# A8107M register map
Vendor: Amiccom Electronics Co., Ltd.; Series: A8107M; File version: 1.0
CPU: CM0 r0p0, little endian, no MPU, no FPU, 2 interrupt priority bits
Registers are 32-bit, read-write, reset 0x0 unless marked. A register's access mark holds for its fields unless they carry their own. Offsets are from the block's base; [hi:lo] are bit positions; {n}, {i} and the like mark numbered series; 'fields as' and 'values as' point back to an identical list.

## GPIO0 (part 2 of 2) — General Purpose I/O
Base 0x40010000
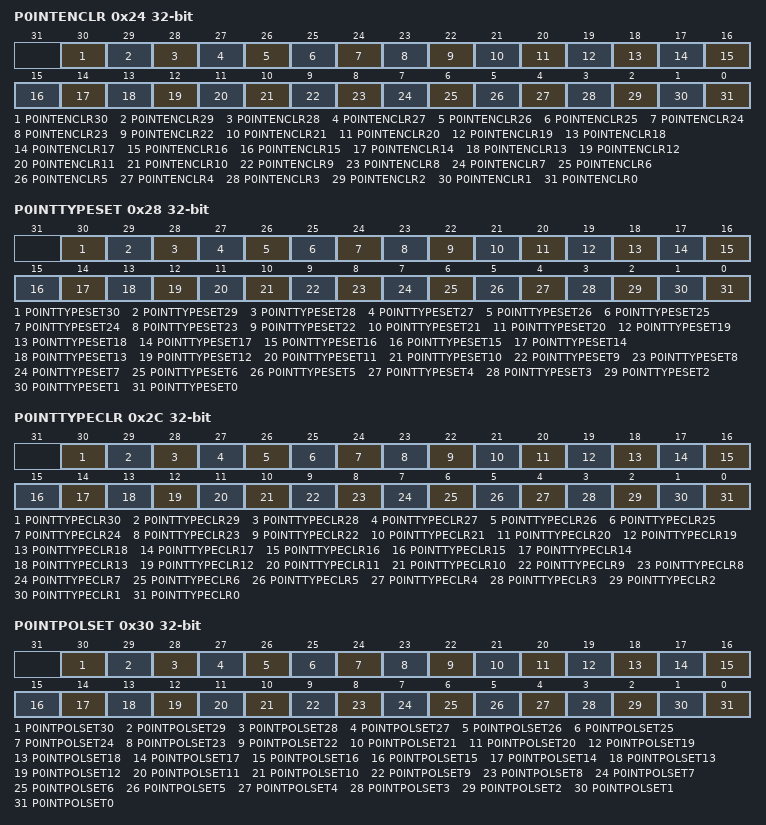
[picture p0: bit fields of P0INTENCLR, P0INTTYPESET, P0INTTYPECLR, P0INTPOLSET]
0x24 P0INTENCLR — Port 0 Interrupt Enable Clear Register
  [30] P0INTENCLR30 — Interrupt Enable Clear of GPIO0.30
    0=No effect; 1=Interrupt Enable Clear of GPIO0.30
  [29] P0INTENCLR29 — Interrupt Enable Clear of GPIO0.29
    0=No effect; 1=Interrupt Enable Clear of GPIO0.29
  [28] P0INTENCLR28 — Interrupt Enable Clear of GPIO0.28
    0=No effect; 1=Interrupt Enable Clear of GPIO0.28
  [27] P0INTENCLR27 — Interrupt Enable Clear of GPIO0.27
    0=No effect; 1=No effect
  [26] P0INTENCLR26 — Interrupt Enable Clear of GPIO0.26
    0=No effect; 1=Interrupt Enable Clear of GPIO0.26
  [25] P0INTENCLR25 — Interrupt Enable Clear of GPIO0.25
    0=No effect; 1=Interrupt Enable Clear of GPIO0.25
  [24] P0INTENCLR24 — Interrupt Enable Clear of GPIO0.24
    0=No effect; 1=Interrupt Enable Clear of GPIO0.24
  [23] P0INTENCLR23 — Interrupt Enable Clear of GPIO0.23
    0=No effect; 1=Interrupt Enable Clear of GPIO0.23
  [22] P0INTENCLR22 — Interrupt Enable Clear of GPIO0.22
    0=No effect; 1=Interrupt Enable Clear of GPIO0.22
  [21] P0INTENCLR21 — Interrupt Enable Clear of GPIO0.21
    0=No effect; 1=Interrupt Enable Clear of GPIO0.21
  [20] P0INTENCLR20 — Interrupt Enable Clear of GPIO0.20
    0=No effect; 1=Interrupt Enable Clear of GPIO0.20
  [19] P0INTENCLR19 — Interrupt Enable Clear of GPIO0.19
    0=No effect; 1=Interrupt Enable Clear of GPIO0.19
  [18] P0INTENCLR18 — Interrupt Enable Clear of GPIO0.18
    0=No effect; 1=Interrupt Enable Clear of GPIO0.18
  [17] P0INTENCLR17 — Interrupt Enable Clear of GPIO0.17
    0=No effect; 1=Interrupt Enable Clear of GPIO0.17
  [16] P0INTENCLR16 — Interrupt Enable Clear of GPIO0.16
    0=No effect; 1=Interrupt Enable Clear of GPIO0.16
  [15] P0INTENCLR15 — Interrupt Enable Clear of GPIO0.15
    0=No effect; 1=Interrupt Enable Clear of GPIO0.15
  [14] P0INTENCLR14 — Interrupt Enable Clear of GPIO0.14
    0=No effect; 1=Interrupt Enable Clear of GPIO0.14
  [13] P0INTENCLR13 — Interrupt Enable Clear of GPIO0.13
    0=No effect; 1=Interrupt Enable Clear of GPIO0.13
  [12] P0INTENCLR12 — Interrupt Enable Clear of GPIO0.12
    0=No effect; 1=Interrupt Enable Clear of GPIO0.12
  [11] P0INTENCLR11 — Interrupt Enable Clear of GPIO0.11
    0=No effect; 1=Interrupt Enable Clear of GPIO0.11
  [10] P0INTENCLR10 — Interrupt Enable Clear of GPIO0.10
    0=No effect; 1=Interrupt Enable Clear of GPIO0.10
  [9] P0INTENCLR9 — Interrupt Enable Clear of GPIO0.9
    0=No effect; 1=Interrupt Enable Clear of GPIO0.9
  [8] P0INTENCLR8 — Interrupt Enable Clear of GPIO0.8
    0=No effect; 1=Interrupt Enable Clear of GPIO0.8
  [7] P0INTENCLR7 — Interrupt Enable Clear of GPIO0.7
    0=No effect; 1=Interrupt Enable Clear of GPIO0.7
  [6] P0INTENCLR6 — Interrupt Enable Clear of GPIO0.6
    0=No effect; 1=Interrupt Enable Clear of GPIO0.6
  [5] P0INTENCLR5 — Interrupt Enable Clear of GPIO0.5
    0=No effect; 1=Interrupt Enable Clear of GPIO0.5
  [4] P0INTENCLR4 — Interrupt Enable Clear of GPIO0.4
    0=No effect; 1=Interrupt Enable Clear of GPIO0.4
  [3] P0INTENCLR3 — Interrupt Enable Clear of GPIO0.3
    0=No effect; 1=Interrupt Enable Clear of GPIO0.3
  [2] P0INTENCLR2 — Interrupt Enable Clear of GPIO0.2
    0=No effect; 1=Interrupt Enable Clear of GPIO0.2
  [1] P0INTENCLR1 — Interrupt Enable Clear of GPIO0.1
    0=No effect; 1=Interrupt Enable Clear of GPIO0.1
  [0] P0INTENCLR0 — Interrupt Enable Clear of GPIO0.0
    0=No effect; 1=Interrupt Enable Clear of GPIO0.0
0x28 P0INTTYPESET — Port 0 Interrupt Type Set Register
  [30] P0INTTYPESET30 — Interrupt type set (interrupt by edge) of GPIO0.30
    0=No effect; 1=Interrupt type set (interrupt by edge) of GPIO0.30
  [29] P0INTTYPESET29 — Interrupt type set (interrupt by edge) of GPIO0.29
    0=No effect; 1=Interrupt type set (interrupt by edge) of GPIO0.29
  [28] P0INTTYPESET28 — Interrupt type set (interrupt by edge) of GPIO0.28
    0=No effect; 1=Interrupt type set (interrupt by edge) of GPIO0.28
  [27] P0INTTYPESET27 — Interrupt type set (interrupt by edge) of GPIO0.27
    0=No effect; 1=No effect
  [26] P0INTTYPESET26 — Interrupt type set (interrupt by edge) of GPIO0.26
    0=No effect; 1=Interrupt type set (interrupt by edge) of GPIO0.26
  [25] P0INTTYPESET25 — Interrupt type set (interrupt by edge) of GPIO0.25
    0=No effect; 1=Interrupt type set (interrupt by edge) of GPIO0.25
  [24] P0INTTYPESET24 — Interrupt type set (interrupt by edge) of GPIO0.24
    0=No effect; 1=Interrupt type set (interrupt by edge) of GPIO0.24
  [23] P0INTTYPESET23 — Interrupt type set (interrupt by edge) of GPIO0.23
    0=No effect; 1=Interrupt type set (interrupt by edge) of GPIO0.23
  [22] P0INTTYPESET22 — Interrupt type set (interrupt by edge) of GPIO0.22
    0=No effect; 1=Interrupt type set (interrupt by edge) of GPIO0.22
  [21] P0INTTYPESET21 — Interrupt type set (interrupt by edge) of GPIO0.21
    0=No effect; 1=Interrupt type set (interrupt by edge) of GPIO0.21
  [20] P0INTTYPESET20 — Interrupt type set (interrupt by edge) of GPIO0.20
    0=No effect; 1=Interrupt type set (interrupt by edge) of GPIO0.20
  [19] P0INTTYPESET19 — Interrupt type set (interrupt by edge) of GPIO0.19
    0=No effect; 1=Interrupt type set (interrupt by edge) of GPIO0.19
  [18] P0INTTYPESET18 — Interrupt type set (interrupt by edge) of GPIO0.18
    0=No effect; 1=Interrupt type set (interrupt by edge) of GPIO0.18
  [17] P0INTTYPESET17 — Interrupt type set (interrupt by edge) of GPIO0.17
    0=No effect; 1=Interrupt type set (interrupt by edge) of GPIO0.17
  [16] P0INTTYPESET16 — Interrupt type set (interrupt by edge) of GPIO0.16
    0=No effect; 1=Interrupt type set (interrupt by edge) of GPIO0.16
  [15] P0INTTYPESET15 — Interrupt type set (interrupt by edge) of GPIO0.15
    0=No effect; 1=Interrupt type set (interrupt by edge) of GPIO0.15
  [14] P0INTTYPESET14 — Interrupt type set (interrupt by edge) of GPIO0.14
    0=No effect; 1=Interrupt type set (interrupt by edge) of GPIO0.14
  [13] P0INTTYPESET13 — Interrupt type set (interrupt by edge) of GPIO0.13
    0=No effect; 1=Interrupt type set (interrupt by edge) of GPIO0.13
  [12] P0INTTYPESET12 — Interrupt type set (interrupt by edge) of GPIO0.12
    0=No effect; 1=Interrupt type set (interrupt by edge) of GPIO0.12
  [11] P0INTTYPESET11 — Interrupt type set (interrupt by edge) of GPIO0.11
    0=No effect; 1=Interrupt type set (interrupt by edge) of GPIO0.11
  [10] P0INTTYPESET10 — Interrupt type set (interrupt by edge) of GPIO0.10
    0=No effect; 1=Interrupt type set (interrupt by edge) of GPIO0.10
  [9] P0INTTYPESET9 — Interrupt type set (interrupt by edge) of GPIO0.9
    0=No effect; 1=Interrupt type set (interrupt by edge) of GPIO0.9
  [8] P0INTTYPESET8 — Interrupt type set (interrupt by edge) of GPIO0.8
    0=No effect; 1=Interrupt type set (interrupt by edge) of GPIO0.8
  [7] P0INTTYPESET7 — Interrupt type set (interrupt by edge) of GPIO0.7
    0=No effect; 1=Interrupt type set (interrupt by edge) of GPIO0.7
  [6] P0INTTYPESET6 — Interrupt type set (interrupt by edge) of GPIO0.6
    0=No effect; 1=Interrupt type set (interrupt by edge) of GPIO0.6
  [5] P0INTTYPESET5 — Interrupt type set (interrupt by edge) of GPIO0.5
    0=No effect; 1=Interrupt type set (interrupt by edge) of GPIO0.5
  [4] P0INTTYPESET4 — Interrupt type set (interrupt by edge) of GPIO0.4
    0=No effect; 1=Interrupt type set (interrupt by edge) of GPIO0.4
  [3] P0INTTYPESET3 — Interrupt type set (interrupt by edge) of GPIO0.3
    0=No effect; 1=Interrupt type set (interrupt by edge) of GPIO0.3
  [2] P0INTTYPESET2 — Interrupt type set (interrupt by edge) of GPIO0.2
    0=No effect; 1=Interrupt type set (interrupt by edge) of GPIO0.2
  [1] P0INTTYPESET1 — Interrupt type set (interrupt by edge) of GPIO0.1
    0=No effect; 1=Interrupt type set (interrupt by edge) of GPIO0.1
  [0] P0INTTYPESET0 — Interrupt type set (interrupt by edge) of GPIO0.0
    0=No effect; 1=Interrupt type set (interrupt by edge) of GPIO0.0
0x2C P0INTTYPECLR — Port 0 Interrupt Type Clear Register
  [30] P0INTTYPECLR30 — Interrupt type clean (interrupt by level) of GPIO0.30
    0=No effect; 1=Interrupt type clean (interrupt by level) of GPIO0.30
  [29] P0INTTYPECLR29 — Interrupt type clean (interrupt by level) of GPIO0.29
    0=No effect; 1=Interrupt type clean (interrupt by level) of GPIO0.29
  [28] P0INTTYPECLR28 — Interrupt type clean (interrupt by level) of GPIO0.28
    0=No effect; 1=Interrupt type clean (interrupt by level) of GPIO0.28
  [27] P0INTTYPECLR27 — Interrupt type clean (interrupt by level) of GPIO0.27
    0=No effect; 1=No effect
  [26] P0INTTYPECLR26 — Interrupt type clean (interrupt by level) of GPIO0.26
    0=No effect; 1=Interrupt type clean (interrupt by level) of GPIO0.26
  [25] P0INTTYPECLR25 — Interrupt type clean (interrupt by level) of GPIO0.25
    0=No effect; 1=Interrupt type clean (interrupt by level) of GPIO0.25
  [24] P0INTTYPECLR24 — Interrupt type clean (interrupt by level) of GPIO0.24
    0=No effect; 1=Interrupt type clean (interrupt by level) of GPIO0.24
  [23] P0INTTYPECLR23 — Interrupt type clean (interrupt by level) of GPIO0.23
    0=No effect; 1=Interrupt type clean (interrupt by level) of GPIO0.23
  [22] P0INTTYPECLR22 — Interrupt type clean (interrupt by level) of GPIO0.22
    0=No effect; 1=Interrupt type clean (interrupt by level) of GPIO0.22
  [21] P0INTTYPECLR21 — Interrupt type clean (interrupt by level) of GPIO0.21
    0=No effect; 1=Interrupt type clean (interrupt by level) of GPIO0.21
  [20] P0INTTYPECLR20 — Interrupt type clean (interrupt by level) of GPIO0.20
    0=No effect; 1=Interrupt type clean (interrupt by level) of GPIO0.20
  [19] P0INTTYPECLR19 — Interrupt type clean (interrupt by level) of GPIO0.19
    0=No effect; 1=Interrupt type clean (interrupt by level) of GPIO0.19
  [18] P0INTTYPECLR18 — Interrupt type clean (interrupt by level) of GPIO0.18
    0=No effect; 1=Interrupt type clean (interrupt by level) of GPIO0.18
  [17] P0INTTYPECLR17 — Interrupt type clean (interrupt by level) of GPIO0.17
    0=No effect; 1=Interrupt type clean (interrupt by level) of GPIO0.17
  [16] P0INTTYPECLR16 — Interrupt type clean (interrupt by level) of GPIO0.16
    0=No effect; 1=Interrupt type clean (interrupt by level) of GPIO0.16
  [15] P0INTTYPECLR15 — Interrupt type clean (interrupt by level) of GPIO0.15
    0=No effect; 1=Interrupt type clean (interrupt by level) of GPIO0.15
  [14] P0INTTYPECLR14 — Interrupt type clean (interrupt by level) of GPIO0.14
    0=No effect; 1=Interrupt type clean (interrupt by level) of GPIO0.14
  [13] P0INTTYPECLR13 — Interrupt type clean (interrupt by level) of GPIO0.13
    0=No effect; 1=Interrupt type clean (interrupt by level) of GPIO0.13
  [12] P0INTTYPECLR12 — Interrupt type clean (interrupt by level) of GPIO0.12
    0=No effect; 1=Interrupt type clean (interrupt by level) of GPIO0.12
  [11] P0INTTYPECLR11 — Interrupt type clean (interrupt by level) of GPIO0.11
    0=No effect; 1=Interrupt type clean (interrupt by level) of GPIO0.11
  [10] P0INTTYPECLR10 — Interrupt type clean (interrupt by level) of GPIO0.10
    0=No effect; 1=Interrupt type clean (interrupt by level) of GPIO0.10
  [9] P0INTTYPECLR9 — Interrupt type clean (interrupt by level) of GPIO0.9
    0=No effect; 1=Interrupt type clean (interrupt by level) of GPIO0.9
  [8] P0INTTYPECLR8 — Interrupt type clean (interrupt by level) of GPIO0.8
    0=No effect; 1=Interrupt type clean (interrupt by level) of GPIO0.8
  [7] P0INTTYPECLR7 — Interrupt type clean (interrupt by level) of GPIO0.7
    0=No effect; 1=Interrupt type clean (interrupt by level) of GPIO0.7
  [6] P0INTTYPECLR6 — Interrupt type clean (interrupt by level) of GPIO0.6
    0=No effect; 1=Interrupt type clean (interrupt by level) of GPIO0.6
  [5] P0INTTYPECLR5 — Interrupt type clean (interrupt by level) of GPIO0.5
    0=No effect; 1=Interrupt type clean (interrupt by level) of GPIO0.5
  [4] P0INTTYPECLR4 — Interrupt type clean (interrupt by level) of GPIO0.4
    0=No effect; 1=Interrupt type clean (interrupt by level) of GPIO0.4
  [3] P0INTTYPECLR3 — Interrupt type clean (interrupt by level) of GPIO0.3
    0=No effect; 1=Interrupt type clean (interrupt by level) of GPIO0.3
  [2] P0INTTYPECLR2 — Interrupt type clean (interrupt by level) of GPIO0.2
    0=No effect; 1=Interrupt type clean (interrupt by level) of GPIO0.2
  [1] P0INTTYPECLR1 — Interrupt type clean (interrupt by level) of GPIO0.1
    0=No effect; 1=Interrupt type clean (interrupt by level) of GPIO0.1
  [0] P0INTTYPECLR0 — Interrupt type clean (interrupt by level) of GPIO0.0
    0=No effect; 1=Interrupt type clean (interrupt by level) of GPIO0.0
0x30 P0INTPOLSET — Port 0 Interrupt Polarity Set Register
  [30] P0INTPOLSET30 — Interrupt Polarity-level clean (low level or falling edge) of GPIO0.30
    0=No effect; 1=Interrupt Polarity-level clean (low level or falling edge) of GPIO0.30
  [29] P0INTPOLSET29 — Interrupt Polarity-level clean (low level or falling edge) of GPIO0.29
    0=No effect; 1=Interrupt Polarity-level clean (low level or falling edge) of GPIO0.29
  [28] P0INTPOLSET28 — Interrupt Polarity-level clean (low level or falling edge) of GPIO0.28
    0=No effect; 1=Interrupt Polarity-level clean (low level or falling edge) of GPIO0.28
  [27] P0INTPOLSET27 — Interrupt Polarity-level clean (low level or falling edge) of GPIO0.27
    0=No effect; 1=No effect
  [26] P0INTPOLSET26 — Interrupt Polarity-level clean (low level or falling edge) of GPIO0.26
    0=No effect; 1=Interrupt Polarity-level clean (low level or falling edge) of GPIO0.26
  [25] P0INTPOLSET25 — Interrupt Polarity-level clean (low level or falling edge) of GPIO0.25
    0=No effect; 1=Interrupt Polarity-level clean (low level or falling edge) of GPIO0.25
  [24] P0INTPOLSET24 — Interrupt Polarity-level clean (low level or falling edge) of GPIO0.24
    0=No effect; 1=Interrupt Polarity-level clean (low level or falling edge) of GPIO0.24
  [23] P0INTPOLSET23 — Interrupt Polarity-level clean (low level or falling edge) of GPIO0.23
    0=No effect; 1=Interrupt Polarity-level clean (low level or falling edge) of GPIO0.23
  [22] P0INTPOLSET22 — Interrupt Polarity-level clean (low level or falling edge) of GPIO0.22
    0=No effect; 1=Interrupt Polarity-level clean (low level or falling edge) of GPIO0.22
  [21] P0INTPOLSET21 — Interrupt Polarity-level clean (low level or falling edge) of GPIO0.21
    0=No effect; 1=Interrupt Polarity-level clean (low level or falling edge) of GPIO0.21
  [20] P0INTPOLSET20 — Interrupt Polarity-level clean (low level or falling edge) of GPIO0.20
    0=No effect; 1=Interrupt Polarity-level clean (low level or falling edge) of GPIO0.20
  [19] P0INTPOLSET19 — Interrupt Polarity-level clean (low level or falling edge) of GPIO0.19
    0=No effect; 1=Interrupt Polarity-level clean (low level or falling edge) of GPIO0.19
  [18] P0INTPOLSET18 — Interrupt Polarity-level clean (low level or falling edge) of GPIO0.18
    0=No effect; 1=Interrupt Polarity-level clean (low level or falling edge) of GPIO0.18
  [17] P0INTPOLSET17 — Interrupt Polarity-level clean (low level or falling edge) of GPIO0.17
    0=No effect; 1=Interrupt Polarity-level clean (low level or falling edge) of GPIO0.17
  [16] P0INTPOLSET16 — Interrupt Polarity-level clean (low level or falling edge) of GPIO0.16
    0=No effect; 1=Interrupt Polarity-level clean (low level or falling edge) of GPIO0.16
  [15] P0INTPOLSET15 — Interrupt Polarity-level clean (low level or falling edge) of GPIO0.15
    0=No effect; 1=Interrupt Polarity-level clean (low level or falling edge) of GPIO0.15
  [14] P0INTPOLSET14 — Interrupt Polarity-level clean (low level or falling edge) of GPIO0.14
    0=No effect; 1=Interrupt Polarity-level clean (low level or falling edge) of GPIO0.14
  [13] P0INTPOLSET13 — Interrupt Polarity-level clean (low level or falling edge) of GPIO0.13
    0=No effect; 1=Interrupt Polarity-level clean (low level or falling edge) of GPIO0.13
  [12] P0INTPOLSET12 — Interrupt Polarity-level clean (low level or falling edge) of GPIO0.12
    0=No effect; 1=Interrupt Polarity-level clean (low level or falling edge) of GPIO0.12
  [11] P0INTPOLSET11 — Interrupt Polarity-level clean (low level or falling edge) of GPIO0.11
    0=No effect; 1=Interrupt Polarity-level clean (low level or falling edge) of GPIO0.11
  [10] P0INTPOLSET10 — Interrupt Polarity-level clean (low level or falling edge) of GPIO0.10
    0=No effect; 1=Interrupt Polarity-level clean (low level or falling edge) of GPIO0.10
  [9] P0INTPOLSET9 — Interrupt Polarity-level clean (low level or falling edge) of GPIO0.9
    0=No effect; 1=Interrupt Polarity-level clean (low level or falling edge) of GPIO0.9
  [8] P0INTPOLSET8 — Interrupt Polarity-level clean (low level or falling edge) of GPIO0.8
    0=No effect; 1=Interrupt Polarity-level clean (low level or falling edge) of GPIO0.8
  [7] P0INTPOLSET7 — Interrupt Polarity-level clean (low level or falling edge) of GPIO0.7
    0=No effect; 1=Interrupt Polarity-level clean (low level or falling edge) of GPIO0.7
  [6] P0INTPOLSET6 — Interrupt Polarity-level clean (low level or falling edge) of GPIO0.6
    0=No effect; 1=Interrupt Polarity-level clean (low level or falling edge) of GPIO0.6
  [5] P0INTPOLSET5 — Interrupt Polarity-level clean (low level or falling edge) of GPIO0.5
    0=No effect; 1=Interrupt Polarity-level clean (low level or falling edge) of GPIO0.5
  [4] P0INTPOLSET4 — Interrupt Polarity-level clean (low level or falling edge) of GPIO0.4
    0=No effect; 1=Interrupt Polarity-level clean (low level or falling edge) of GPIO0.4
  [3] P0INTPOLSET3 — Interrupt Polarity-level clean (low level or falling edge) of GPIO0.3
    0=No effect; 1=Interrupt Polarity-level clean (low level or falling edge) of GPIO0.3
  [2] P0INTPOLSET2 — Interrupt Polarity-level clean (low level or falling edge) of GPIO0.2
    0=No effect; 1=Interrupt Polarity-level clean (low level or falling edge) of GPIO0.2
  [1] P0INTPOLSET1 — Interrupt Polarity-level clean (low level or falling edge) of GPIO0.1
    0=No effect; 1=Interrupt Polarity-level clean (low level or falling edge) of GPIO0.1
  [0] P0INTPOLSET0 — Interrupt Polarity-level clean (low level or falling edge) of GPIO0.0
    0=No effect; 1=Interrupt Polarity-level clean (low level or falling edge) of GPIO0.0
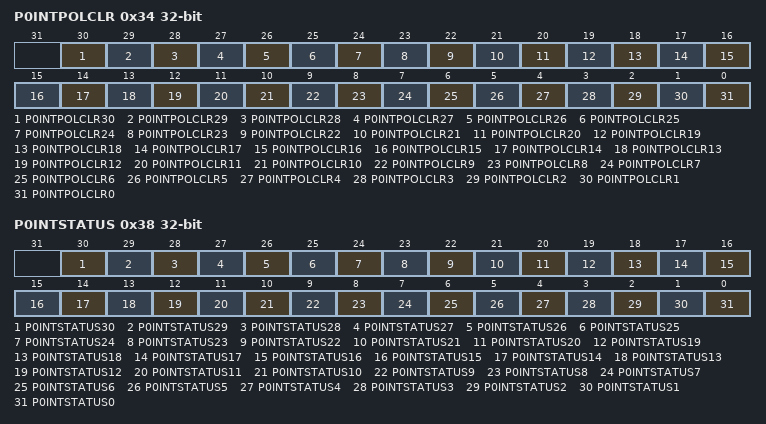
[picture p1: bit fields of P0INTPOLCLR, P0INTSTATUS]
0x34 P0INTPOLCLR — Port 0 Interrupt Polarity Clear Register
  [30] P0INTPOLCLR30 — Interrupt Polarity-level clean (low level or falling edge) of GPIO0.30
    values as P0INTPOLSET.P0INTPOLSET30
  [29] P0INTPOLCLR29 — Interrupt Polarity-level clean (low level or falling edge) of GPIO0.29
    values as P0INTPOLSET.P0INTPOLSET29
  [28] P0INTPOLCLR28 — Interrupt Polarity-level clean (low level or falling edge) of GPIO0.28
    values as P0INTPOLSET.P0INTPOLSET28
  [27] P0INTPOLCLR27 — Interrupt Polarity-level clean (low level or falling edge) of GPIO0.27
    0=No effect; 1=No effect
  [26] P0INTPOLCLR26 — Interrupt Polarity-level clean (low level or falling edge) of GPIO0.26
    values as P0INTPOLSET.P0INTPOLSET26
  [25] P0INTPOLCLR25 — Interrupt Polarity-level clean (low level or falling edge) of GPIO0.25
    values as P0INTPOLSET.P0INTPOLSET25
  [24] P0INTPOLCLR24 — Interrupt Polarity-level clean (low level or falling edge) of GPIO0.24
    values as P0INTPOLSET.P0INTPOLSET24
  [23] P0INTPOLCLR23 — Interrupt Polarity-level clean (low level or falling edge) of GPIO0.23
    values as P0INTPOLSET.P0INTPOLSET23
  [22] P0INTPOLCLR22 — Interrupt Polarity-level clean (low level or falling edge) of GPIO0.22
    values as P0INTPOLSET.P0INTPOLSET22
  [21] P0INTPOLCLR21 — Interrupt Polarity-level clean (low level or falling edge) of GPIO0.21
    values as P0INTPOLSET.P0INTPOLSET21
  [20] P0INTPOLCLR20 — Interrupt Polarity-level clean (low level or falling edge) of GPIO0.20
    values as P0INTPOLSET.P0INTPOLSET20
  [19] P0INTPOLCLR19 — Interrupt Polarity-level clean (low level or falling edge) of GPIO0.19
    values as P0INTPOLSET.P0INTPOLSET19
  [18] P0INTPOLCLR18 — Interrupt Polarity-level clean (low level or falling edge) of GPIO0.18
    values as P0INTPOLSET.P0INTPOLSET18
  [17] P0INTPOLCLR17 — Interrupt Polarity-level clean (low level or falling edge) of GPIO0.17
    values as P0INTPOLSET.P0INTPOLSET17
  [16] P0INTPOLCLR16 — Interrupt Polarity-level clean (low level or falling edge) of GPIO0.16
    values as P0INTPOLSET.P0INTPOLSET16
  [15] P0INTPOLCLR15 — Interrupt Polarity-level clean (low level or falling edge) of GPIO0.15
    values as P0INTPOLSET.P0INTPOLSET15
  [14] P0INTPOLCLR14 — Interrupt Polarity-level clean (low level or falling edge) of GPIO0.14
    values as P0INTPOLSET.P0INTPOLSET14
  [13] P0INTPOLCLR13 — Interrupt Polarity-level clean (low level or falling edge) of GPIO0.13
    values as P0INTPOLSET.P0INTPOLSET13
  [12] P0INTPOLCLR12 — Interrupt Polarity-level clean (low level or falling edge) of GPIO0.12
    values as P0INTPOLSET.P0INTPOLSET12
  [11] P0INTPOLCLR11 — Interrupt Polarity-level clean (low level or falling edge) of GPIO0.11
    values as P0INTPOLSET.P0INTPOLSET11
  [10] P0INTPOLCLR10 — Interrupt Polarity-level clean (low level or falling edge) of GPIO0.10
    values as P0INTPOLSET.P0INTPOLSET10
  [9] P0INTPOLCLR9 — Interrupt Polarity-level clean (low level or falling edge) of GPIO0.9
    values as P0INTPOLSET.P0INTPOLSET9
  [8] P0INTPOLCLR8 — Interrupt Polarity-level clean (low level or falling edge) of GPIO0.8
    values as P0INTPOLSET.P0INTPOLSET8
  [7] P0INTPOLCLR7 — Interrupt Polarity-level clean (low level or falling edge) of GPIO0.7
    values as P0INTPOLSET.P0INTPOLSET7
  [6] P0INTPOLCLR6 — Interrupt Polarity-level clean (low level or falling edge) of GPIO0.6
    values as P0INTPOLSET.P0INTPOLSET6
  [5] P0INTPOLCLR5 — Interrupt Polarity-level clean (low level or falling edge) of GPIO0.5
    values as P0INTPOLSET.P0INTPOLSET5
  [4] P0INTPOLCLR4 — Interrupt Polarity-level clean (low level or falling edge) of GPIO0.4
    values as P0INTPOLSET.P0INTPOLSET4
  [3] P0INTPOLCLR3 — Interrupt Polarity-level clean (low level or falling edge) of GPIO0.3
    values as P0INTPOLSET.P0INTPOLSET3
  [2] P0INTPOLCLR2 — Interrupt Polarity-level clean (low level or falling edge) of GPIO0.2
    values as P0INTPOLSET.P0INTPOLSET2
  [1] P0INTPOLCLR1 — Interrupt Polarity-level clean (low level or falling edge) of GPIO0.1
    values as P0INTPOLSET.P0INTPOLSET1
  [0] P0INTPOLCLR0 — Interrupt Polarity-level clean (low level or falling edge) of GPIO0.0
    values as P0INTPOLSET.P0INTPOLSET0
0x38 P0INTSTATUS ro — Port 0 Interrupt Request Status Register
  [30] P0INTSTATUS30 rw — Clear interrupt request status of GPIO0.30
    0=No effect; 1=Clear interrupt request status of GPIO0.30
  [29] P0INTSTATUS29 rw — Clear interrupt request status of GPIO0.29
    0=No effect; 1=Clear interrupt request status of GPIO0.29
  [28] P0INTSTATUS28 rw — Clear interrupt request status of GPIO0.28
    0=No effect; 1=Clear interrupt request status of GPIO0.28
  [27] P0INTSTATUS27 rw — Clear interrupt request status of GPIO0.27
    0=No effect; 1=No effect
  [26] P0INTSTATUS26 rw — Clear interrupt request status of GPIO0.26
    0=No effect; 1=Clear interrupt request status of GPIO0.26
  [25] P0INTSTATUS25 rw — Clear interrupt request status of GPIO0.25
    0=No effect; 1=Clear interrupt request status of GPIO0.25
  [24] P0INTSTATUS24 rw — Clear interrupt request status of GPIO0.24
    0=No effect; 1=Clear interrupt request status of GPIO0.24
  [23] P0INTSTATUS23 rw — Clear interrupt request status of GPIO0.23
    0=No effect; 1=Clear interrupt request status of GPIO0.23
  [22] P0INTSTATUS22 rw — Clear interrupt request status of GPIO0.22
    0=No effect; 1=Clear interrupt request status of GPIO0.22
  [21] P0INTSTATUS21 rw — Clear interrupt request status of GPIO0.21
    0=No effect; 1=Clear interrupt request status of GPIO0.21
  [20] P0INTSTATUS20 rw — Clear interrupt request status of GPIO0.20
    0=No effect; 1=Clear interrupt request status of GPIO0.20
  [19] P0INTSTATUS19 rw — Clear interrupt request status of GPIO0.19
    0=No effect; 1=Clear interrupt request status of GPIO0.19
  [18] P0INTSTATUS18 rw — Clear interrupt request status of GPIO0.18
    0=No effect; 1=Clear interrupt request status of GPIO0.18
  [17] P0INTSTATUS17 rw — Clear interrupt request status of GPIO0.17
    0=No effect; 1=Clear interrupt request status of GPIO0.17
  [16] P0INTSTATUS16 rw — Clear interrupt request status of GPIO0.16
    0=No effect; 1=Clear interrupt request status of GPIO0.16
  [15] P0INTSTATUS15 rw — Clear interrupt request status of GPIO0.15
    0=No effect; 1=Clear interrupt request status of GPIO0.15
  [14] P0INTSTATUS14 rw — Clear interrupt request status of GPIO0.14
    0=No effect; 1=Clear interrupt request status of GPIO0.14
  [13] P0INTSTATUS13 rw — Clear interrupt request status of GPIO0.13
    0=No effect; 1=Clear interrupt request status of GPIO0.13
  [12] P0INTSTATUS12 rw — Clear interrupt request status of GPIO0.12
    0=No effect; 1=Clear interrupt request status of GPIO0.12
  [11] P0INTSTATUS11 rw — Clear interrupt request status of GPIO0.11
    0=No effect; 1=Clear interrupt request status of GPIO0.11
  [10] P0INTSTATUS10 rw — Clear interrupt request status of GPIO0.10
    0=No effect; 1=Clear interrupt request status of GPIO0.10
  [9] P0INTSTATUS9 rw — Clear interrupt request status of GPIO0.9
    0=No effect; 1=Clear interrupt request status of GPIO0.9
  [8] P0INTSTATUS8 rw — Clear interrupt request status of GPIO0.8
    0=No effect; 1=Clear interrupt request status of GPIO0.8
  [7] P0INTSTATUS7 rw — Clear interrupt request status of GPIO0.7
    0=No effect; 1=Clear interrupt request status of GPIO0.7
  [6] P0INTSTATUS6 rw — Clear interrupt request status of GPIO0.6
    0=No effect; 1=Clear interrupt request status of GPIO0.6
  [5] P0INTSTATUS5 rw — Clear interrupt request status of GPIO0.5
    0=No effect; 1=Clear interrupt request status of GPIO0.5
  [4] P0INTSTATUS4 rw — Clear interrupt request status of GPIO0.4
    0=No effect; 1=Clear interrupt request status of GPIO0.4
  [3] P0INTSTATUS3 rw — Clear interrupt request status of GPIO0.3
    0=No effect; 1=Clear interrupt request status of GPIO0.3
  [2] P0INTSTATUS2 rw — Clear interrupt request status of GPIO0.2
    0=No effect; 1=Clear interrupt request status of GPIO0.2
  [1] P0INTSTATUS1 rw — Clear interrupt request status of GPIO0.1
    0=No effect; 1=Clear interrupt request status of GPIO0.1
  [0] P0INTSTATUS0 rw — Clear interrupt request status of GPIO0.0
    0=No effect; 1=Clear interrupt request status of GPIO0.0
0x38 P0INTCLEAR wo (reset mask 0x7FFFFFFF) (alternate view of P0INTSTATUS) — Port 0 Interrupt Request Clear Register
{0x400+4i} LB_MASKED[{i}] (i=0..255) — Lower byte Masked Access Register
{0x800+4i} UB_MASKED[{i}] (i=0..255) — Upper byte Masked Access Register
